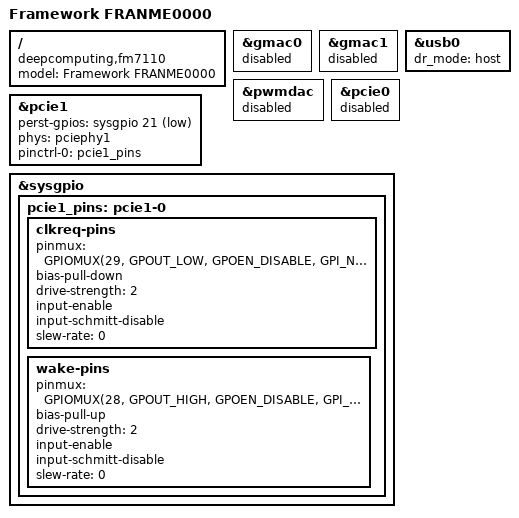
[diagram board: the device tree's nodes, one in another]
// SPDX-License-Identifier: GPL-2.0 OR MIT
/*
 * Copyright (C) 2022 StarFive Technology Co., Ltd.
 * Copyright (C) 2022 Emil Renner Berthing <kernel@esmil.dk>
 */

/dts-v1/;
#include "jh7110-common.dtsi"

/ {
	model = "Framework FRANME0000";
	compatible = "deepcomputing,fm7110", "starfive,jh7110";
};

&gmac0 {
	status = "disabled";
};

&gmac1 {
	status = "disabled";
};

&usb0 {
	dr_mode = "host";
	status = "okay";
};

&pwmdac {
	status = "disabled";
};

&pcie0 {
	status = "disabled";
};

&pcie1 {
	perst-gpios = <&sysgpio 21 GPIO_ACTIVE_LOW>;
	phys = <&pciephy1>;
	pinctrl-names = "default";
	pinctrl-0 = <&pcie1_pins>;
	status = "okay";
};

&sysgpio {
	pcie1_pins: pcie1-0 {
		clkreq-pins {
			pinmux = <GPIOMUX(29, GPOUT_LOW,
					      GPOEN_DISABLE,
					      GPI_NONE)>;
			bias-pull-down;
			drive-strength = <2>;
			input-enable;
			input-schmitt-disable;
			slew-rate = <0>;
		};

		wake-pins {
			pinmux = <GPIOMUX(28, GPOUT_HIGH,
				      GPOEN_DISABLE,
					      GPI_NONE)>;
			bias-pull-up;
			drive-strength = <2>;
			input-enable;
			input-schmitt-disable;
			slew-rate = <0>;
		};
	};
};
